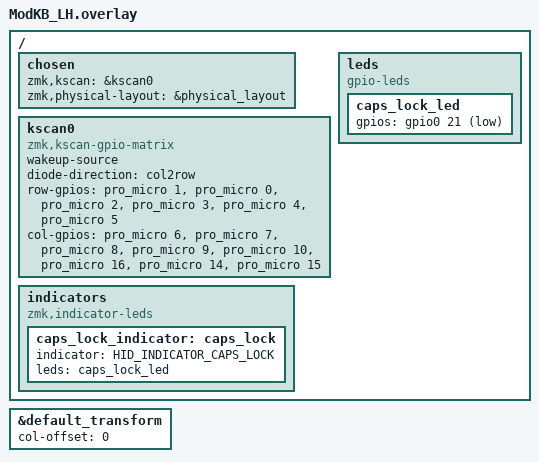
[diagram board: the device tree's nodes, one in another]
#include <dt-bindings/zmk/matrix_transform.h>
#include <dt-bindings/zmk/hid_indicators.h>
#include "ModKB.dtsi"


//transform

    &default_transform {
        col-offset = <0>;
    };
/ {
//chosen
    chosen {
        zmk,kscan = &kscan0;
        zmk,physical-layout = &physical_layout;
    };


//kscan
    // PIN MAPPING LEFT HALF

    // diode move col2row or row2col?

    kscan0: kscan0 { 
        compatible = "zmk,kscan-gpio-matrix";
        wakeup-source;
        diode-direction = "col2row";

        row-gpios
            = <&pro_micro 1 (GPIO_ACTIVE_HIGH | GPIO_PULL_DOWN) > // row 1
            , <&pro_micro 0 (GPIO_ACTIVE_HIGH | GPIO_PULL_DOWN) > // row 2
            , <&pro_micro 2 (GPIO_ACTIVE_HIGH | GPIO_PULL_DOWN) > // row 3
            , <&pro_micro 3 (GPIO_ACTIVE_HIGH | GPIO_PULL_DOWN) > // row 4
            , <&pro_micro 4 (GPIO_ACTIVE_HIGH | GPIO_PULL_DOWN) > // row 5
            , <&pro_micro 5 (GPIO_ACTIVE_HIGH | GPIO_PULL_DOWN) > // row 6
            ;
        col-gpios 
            = <&pro_micro 6 GPIO_ACTIVE_HIGH > // column 1
            , <&pro_micro 7 GPIO_ACTIVE_HIGH > // column 2
            , <&pro_micro 8 GPIO_ACTIVE_HIGH > // column 3
            , <&pro_micro 9 GPIO_ACTIVE_HIGH > // column 4
            , <&pro_micro 10 GPIO_ACTIVE_HIGH > // column 5
            , <&pro_micro 16 GPIO_ACTIVE_HIGH > // column 6
            , <&pro_micro 14 GPIO_ACTIVE_HIGH > // column 7
            , <&pro_micro 15 GPIO_ACTIVE_HIGH > // column 8
            ;
    };




//led and idicators
    // development verison, cant use the library in 0.3V
    leds {
        compatible = "gpio-leds";

        caps_lock_led: caps_lock_led {
            gpios = <&gpio0 21 GPIO_ACTIVE_LOW>;
        };
    };

    indicators {
            compatible = "zmk,indicator-leds";

            caps_lock_indicator: caps_lock {
                indicator = <HID_INDICATOR_CAPS_LOCK>;
                leds = <&caps_lock_led>;
            };
    };

};
